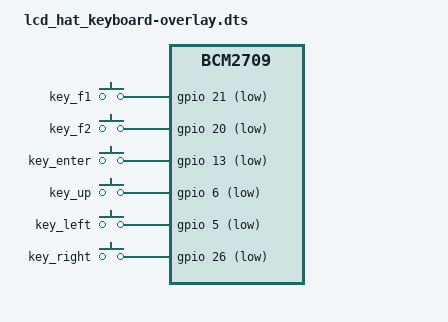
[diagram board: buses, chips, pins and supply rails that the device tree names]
/dts-v1/;
/plugin/;
/ {
    compatible = "brcm,bcm2835", "brcm,bcm2708", "brcm,bcm2709";

    fragment@0 {
        target = <&gpio>;
        __overlay__ {
            butt_pins: butt_pins {
                brcm,pins = <21 20 6 5 26 13>; // gpio no.
                brcm,function = <0 0 0 0 0 0>;   // 0:in, 1:out
                brcm,pull = <2 2 2 2 2 2>;       // 2:up 1:down 0:none
            };
        };
    };

    fragment@1 {
        target-path = "/";
        __overlay__ {
            key123: lcd-hat-keyboard {
                pinctrl-names = "default";
                pinctrl-0 = <&butt_pins>;
                compatible = "gpio-keys";
                status = "okay";
                autorepeat;

                button@21 {
                    label = "key_f1";
                    linux,code = <2>;
                    gpios = <&gpio 21 1>;
                };
                button@20 {
                    label = "key_f2";
                    linux,code = <3>;
                    gpios = <&gpio 20 1>;
                };

                button@13 {
                    label = "key_enter";
                    linux,code = <28>;
                    gpios = <&gpio 13 1>;
                };

                button@6 {
                    label = "key_up";
                    linux,code = <103>;
                    gpios = <&gpio 6 1>;
                };
                button@5 {
                    label = "key_left";
                    linux,code = <105>;
                    gpios = <&gpio 5 1>;
                };
                button@26 {
                    label = "key_right";
                    linux,code = <106>;
                    gpios = <&gpio 26 1>;
                };
            };
        };
    };
};
